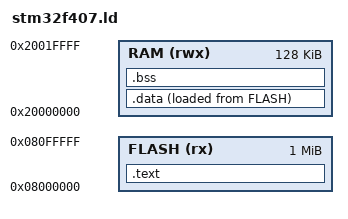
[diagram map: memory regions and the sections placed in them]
MEMORY
{
    FLASH (rx) : ORIGIN = 0x08000000, LENGTH = 1024K
    RAM (rwx)  : ORIGIN = 0x20000000, LENGTH = 128K
}

ENTRY(Reset_Handler)

SECTIONS
{
    .text :
    {
        KEEP(*(.isr_vector))
        *(.text)
        *(.text.*)
        *(.rodata)
        *(.rodata.*)
        . = ALIGN(4);
        _etext = .;
    } > FLASH

    _sidata = LOADADDR(.data);

    .data :
    {
        . = ALIGN(4);
        _sdata = .;
        *(.data)
        *(.data.*)
        . = ALIGN(4);
        _edata = .;
    } > RAM AT > FLASH

    .bss :
    {
        . = ALIGN(4);
        _sbss = .;
        *(.bss)
        *(.bss.*)
        *(COMMON)
        . = ALIGN(4);
        _ebss = .;
    } > RAM
}
